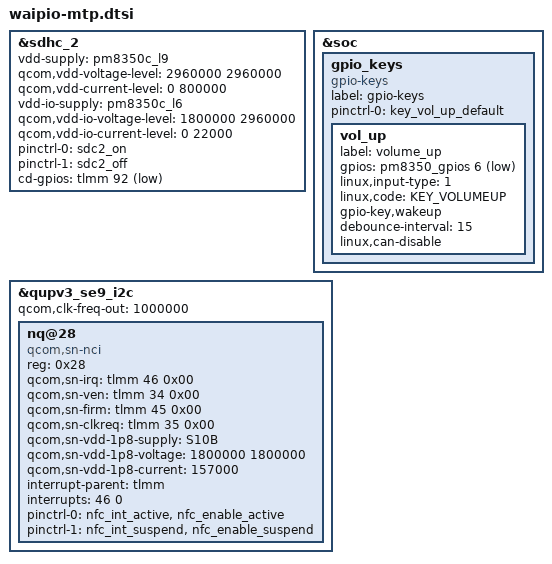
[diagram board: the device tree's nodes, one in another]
#include <dt-bindings/gpio/gpio.h>
#include <dt-bindings/input/input.h>

#include "waipio-pmic-overlay.dtsi"
#include "waipio-audio-overlay.dtsi"

&sdhc_2 {
	status = "ok";
	vdd-supply = <&pm8350c_l9>;
	qcom,vdd-voltage-level = <2960000 2960000>;
	qcom,vdd-current-level = <0 800000>;

	vdd-io-supply = <&pm8350c_l6>;
	qcom,vdd-io-voltage-level = <1800000 2960000>;
	qcom,vdd-io-current-level = <0 22000>;

	pinctrl-names = "default", "sleep";
	pinctrl-0 = <&sdc2_on>;
	pinctrl-1 = <&sdc2_off>;

	cd-gpios = <&tlmm 92 GPIO_ACTIVE_LOW>;
};

&soc {
	gpio_keys {
		compatible = "gpio-keys";
		label = "gpio-keys";

		pinctrl-names = "default";
		pinctrl-0 = <&key_vol_up_default>;

		vol_up {
			label = "volume_up";
			gpios = <&pm8350_gpios 6 GPIO_ACTIVE_LOW>;
			linux,input-type = <1>;
			linux,code = <KEY_VOLUMEUP>;
			gpio-key,wakeup;
			debounce-interval = <15>;
			linux,can-disable;
		};
	};
};

&qupv3_se9_i2c {
	status = "ok";
	qcom,clk-freq-out = <1000000>;
	#address-cells = <1>;
	#size-cells = <0>;
	nq@28 {
		compatible = "qcom,sn-nci";
		reg = <0x28>;
		qcom,sn-irq = <&tlmm 46 0x00>;
		qcom,sn-ven = <&tlmm 34 0x00>;
		qcom,sn-firm = <&tlmm 45 0x00>;
		qcom,sn-clkreq = <&tlmm 35 0x00>;
		qcom,sn-vdd-1p8-supply = <&S10B>;
		qcom,sn-vdd-1p8-voltage = <1800000 1800000>;
		qcom,sn-vdd-1p8-current = <157000>;
		interrupt-parent = <&tlmm>;
		interrupts = <46 0>;
		interrupt-names = "nfc_irq";
		pinctrl-names = "nfc_active", "nfc_suspend";
		pinctrl-0 = <&nfc_int_active &nfc_enable_active>;
		pinctrl-1 = <&nfc_int_suspend &nfc_enable_suspend>;
	};
};
